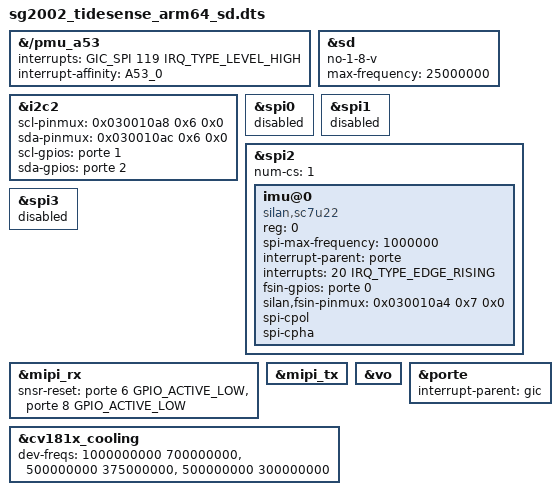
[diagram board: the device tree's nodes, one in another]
/dts-v1/;
#include "cv181x_base_arm.dtsi"
#include "cv181x_asic_bga.dtsi"
#include "cv181x_asic_sd.dtsi"
#include "cv181x_default_memmap.dtsi"

/ {
	/* This board has no SPI NOR or SPI NAND device. */
	/delete-node/ cvi-spif@10000000;
};

&{/pmu_a53} {
	/* SG2002 exposes one A53; each PMU SPI needs one affinity entry. */
	interrupts = <GIC_SPI 119 IRQ_TYPE_LEVEL_HIGH>;
	interrupt-affinity = <&A53_0>;
};

&sd {
	/* SD0_CD is grounded on this board; the TF socket's DET switch is not routed. */
	/delete-property/ cvi-cd-gpios;
	no-1-8-v;
	max-frequency = <25000000>;
};

&i2c2 {
	status = "okay";
	scl-pinmux = <0x030010a8 0x6 0x0>;
	sda-pinmux = <0x030010ac 0x6 0x0>;
	scl-gpios = <&porte 1 GPIO_ACTIVE_HIGH>;
	sda-gpios = <&porte 2 GPIO_ACTIVE_HIGH>;
};

&spi0 {
	status = "disabled";
};

&spi1 {
	status = "disabled";
};

&spi2 {
	status = "okay";
	num-cs = <1>;

	imu@0 {
		compatible = "silan,sc7u22";
		reg = <0>;
		spi-max-frequency = <1000000>;
		/* SC7U22 INT1 -> SD1_D1 / PWR_GPIO20, active high. */
		interrupt-parent = <&porte>;
		interrupts = <20 IRQ_TYPE_EDGE_RISING>;
		/* Shared camera trigger: every 10 INT1 edges, 100 us high. */
		fsin-gpios = <&porte 0 GPIO_ACTIVE_HIGH>;
		silan,fsin-pinmux = <0x030010a4 0x7 0x0>;
		spi-cpol;
		spi-cpha;
	};
};

&spi3 {
	status = "disabled";
};

&mipi_rx {
	/* Camera 0 / Camera 1 XSHUTDOWN, on PWR_WAKEUP0 / PWR_BUTTON1. */
	snsr-reset = <&porte 6 GPIO_ACTIVE_LOW>, <&porte 8 GPIO_ACTIVE_LOW>;
};

/* There is no display panel. These reference-board pins are camera FSIN/I2C. */
&mipi_tx {
	/delete-property/ reset-gpio;
	/delete-property/ pwm-gpio;
	/delete-property/ power-ct-gpio;
};

&vo {
	/delete-property/ reset-gpio;
	/delete-property/ pwm-gpio;
	/delete-property/ power-ct-gpio;
};

&porte {
	/* GPIO interrupt specifiers contain pin number and IRQ trigger flags. */
	#interrupt-cells = <2>;
	interrupt-parent = <&gic>;
};

/* Match the A53-only 1 GHz FSBL setting; retain thermal throttling. */
&cv181x_cooling {
	dev-freqs = <1000000000 700000000>,
		<500000000 375000000>,
		<500000000 300000000>;
};
